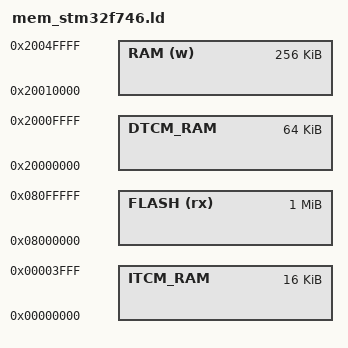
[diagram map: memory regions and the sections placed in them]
MEMORY
{
  RAM (w) : ORIGIN = 0x20010000, LENGTH = 256K
  DTCM_RAM : ORIGIN = 0x20000000, LENGTH = 64K
  ITCM_RAM : ORIGIN = 0x00000000, LENGTH = 16K
  FLASH (rx) : ORIGIN = 0x08000000, LENGTH = 1024K
}
